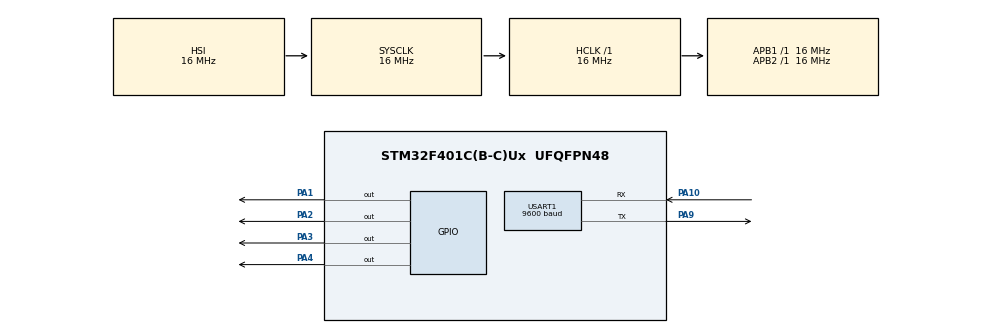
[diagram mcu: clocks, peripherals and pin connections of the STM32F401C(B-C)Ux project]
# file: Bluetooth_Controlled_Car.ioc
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Mcu.Family=STM32F4
Mcu.Name=STM32F401C(B-C)Ux
Mcu.Package=UFQFPN48
NVIC.PriorityGroup=NVIC_PRIORITYGROUP_4
NVIC.USART1_IRQn=true\:0\:0\:false\:false\:true\:true\:true
PA1.Signal=GPIO_Output
PA10.Mode=Asynchronous
PA10.Signal=USART1_RX
PA2.Signal=GPIO_Output
PA3.Signal=GPIO_Output
PA4.Signal=GPIO_Output
PA9.Mode=Asynchronous
PA9.Signal=USART1_TX
PH0\ -\ OSC_IN.Signal=RCC_OSC_IN
PH1\ -\ OSC_OUT.Signal=RCC_OSC_OUT
ProjectManager.HeapSize=0x200
ProjectManager.StackSize=0x400
ProjectManager.TargetToolchain=MDK-ARM V5.27
RCC.AHBFreq_Value=16000000
RCC.APB1Freq_Value=16000000
RCC.APB2Freq_Value=16000000
RCC.CortexFreq_Value=16000000
RCC.HSE_VALUE=25000000
RCC.HSI_VALUE=16000000
RCC.LSE_VALUE=32768
RCC.SYSCLKFreq_VALUE=16000000
RCC.VCOOutputFreq_Value=192000000
USART1.BaudRate=9600
USART1.Mode=MODE_RX
USART1.VirtualMode=VM_ASYNC
board=custom

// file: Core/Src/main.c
/* USER CODE BEGIN Header */
/**
  ******************************************************************************
  * @file           : main.c
  * @brief          : Main program body
  ******************************************************************************
  * @attention
  *
  * <h2><center>&copy; Copyright (c) 2021 STMicroelectronics.
  * All rights reserved.</center></h2>
  *
  * This software component is licensed by ST under BSD 3-Clause license,
  * the "License"; You may not use this file except in compliance with the
  * License. You may obtain a copy of the License at:
  *                        opensource.org/licenses/BSD-3-Clause
  *
  ******************************************************************************
  */
/* USER CODE END Header */
#include "main.h"

#define BUFFER_LEN  1

UART_HandleTypeDef huart1;

/* USER CODE BEGIN PV */

uint8_t RX_BUFFER[BUFFER_LEN] = {0};

/* USER CODE END PV */

void SystemClock_Config(void);
static void MX_GPIO_Init(void);
static void MX_USART1_UART_Init(void);

int main(void)
{

  /* MCU Configuration--------------------------------------------------------*/

  /* Reset of all peripherals, Initializes the Flash interface and the Systick. */
  HAL_Init();

  /* Configure the system clock */
  SystemClock_Config();

  /* Initialize all configured peripherals */
  MX_GPIO_Init();
  MX_USART1_UART_Init();
  /* USER CODE BEGIN 2 */
	HAL_UART_Receive_IT(&huart1, RX_BUFFER, BUFFER_LEN);
  /* USER CODE END 2 */

  /* Infinite loop */
  while (1)
  {
		if(RX_BUFFER[0] == 'F')			// Move Forward
    	{
    	    HAL_GPIO_WritePin(GPIOA, GPIO_PIN_1, 1);
					HAL_GPIO_WritePin(GPIOA, GPIO_PIN_2, 0);
					HAL_GPIO_WritePin(GPIOA, GPIO_PIN_3, 1);
					HAL_GPIO_WritePin(GPIOA, GPIO_PIN_4, 0);
    	}
    	else if(RX_BUFFER[0] == 'B')		// Move Backward
    	{
    	    HAL_GPIO_WritePin(GPIOA, GPIO_PIN_1, 0);
					HAL_GPIO_WritePin(GPIOA, GPIO_PIN_2, 1);
					HAL_GPIO_WritePin(GPIOA, GPIO_PIN_3, 0);
					HAL_GPIO_WritePin(GPIOA, GPIO_PIN_4, 1);
    	}
			else if(RX_BUFFER[0] == 'L')		// Turn Left
    	{
    	    HAL_GPIO_WritePin(GPIOA, GPIO_PIN_1, 1);
					HAL_GPIO_WritePin(GPIOA, GPIO_PIN_2, 0);
					HAL_GPIO_WritePin(GPIOA, GPIO_PIN_3, 0);
					HAL_GPIO_WritePin(GPIOA, GPIO_PIN_4, 1);
					HAL_Delay(1000);  // 1 sec delay
					RX_BUFFER[0] = 'S';
    	}
    	else if(RX_BUFFER[0] == 'R')		// Turn Right
    	{
    	    HAL_GPIO_WritePin(GPIOA, GPIO_PIN_1, 0);
					HAL_GPIO_WritePin(GPIOA, GPIO_PIN_2, 1);
					HAL_GPIO_WritePin(GPIOA, GPIO_PIN_3, 1);
					HAL_GPIO_WritePin(GPIOA, GPIO_PIN_4, 0);
					HAL_Delay(1000);  // 1 sec delay
					RX_BUFFER[0] = 'S';
    	}
			else if(RX_BUFFER[0] == 'S')		// Stop
    	{
    	    HAL_GPIO_WritePin(GPIOA, GPIO_PIN_1, 0);
					HAL_GPIO_WritePin(GPIOA, GPIO_PIN_2, 0);
					HAL_GPIO_WritePin(GPIOA, GPIO_PIN_3, 0);
					HAL_GPIO_WritePin(GPIOA, GPIO_PIN_4, 0);
    	}
  }
}

void HAL_UART_RxCpltCallback(UART_HandleTypeDef *huart)
{
    if(huart->Instance == huart1.Instance)
    {
	HAL_UART_Receive_IT(&huart1, RX_BUFFER, BUFFER_LEN);
    }
}
void SystemClock_Config(void)
{
  RCC_OscInitTypeDef RCC_OscInitStruct = {0};
  RCC_ClkInitTypeDef RCC_ClkInitStruct = {0};

  /** Configure the main internal regulator output voltage
  */
  __HAL_RCC_PWR_CLK_ENABLE();
  __HAL_PWR_VOLTAGESCALING_CONFIG(PWR_REGULATOR_VOLTAGE_SCALE2);
  /** Initializes the RCC Oscillators according to the specified parameters
  * in the RCC_OscInitTypeDef structure.
  */
  RCC_OscInitStruct.OscillatorType = RCC_OSCILLATORTYPE_HSI;
  RCC_OscInitStruct.HSIState = RCC_HSI_ON;
  RCC_OscInitStruct.HSICalibrationValue = RCC_HSICALIBRATION_DEFAULT;
  RCC_OscInitStruct.PLL.PLLState = RCC_PLL_NONE;
  if (HAL_RCC_OscConfig(&RCC_OscInitStruct) != HAL_OK)
  {
    Error_Handler();
  }
  /** Initializes the CPU, AHB and APB buses clocks
  */
  RCC_ClkInitStruct.ClockType = RCC_CLOCKTYPE_HCLK|RCC_CLOCKTYPE_SYSCLK
                              |RCC_CLOCKTYPE_PCLK1|RCC_CLOCKTYPE_PCLK2;
  RCC_ClkInitStruct.SYSCLKSource = RCC_SYSCLKSOURCE_HSI;
  RCC_ClkInitStruct.AHBCLKDivider = RCC_SYSCLK_DIV1;
  RCC_ClkInitStruct.APB1CLKDivider = RCC_HCLK_DIV1;
  RCC_ClkInitStruct.APB2CLKDivider = RCC_HCLK_DIV1;

  if (HAL_RCC_ClockConfig(&RCC_ClkInitStruct, FLASH_LATENCY_0) != HAL_OK)
  {
    Error_Handler();
  }
}

static void MX_USART1_UART_Init(void)
{

  huart1.Instance = USART1;
  huart1.Init.BaudRate = 9600;
  huart1.Init.WordLength = UART_WORDLENGTH_8B;
  huart1.Init.StopBits = UART_STOPBITS_1;
  huart1.Init.Parity = UART_PARITY_NONE;
  huart1.Init.Mode = UART_MODE_RX;
  huart1.Init.HwFlowCtl = UART_HWCONTROL_NONE;
  huart1.Init.OverSampling = UART_OVERSAMPLING_16;
  if (HAL_UART_Init(&huart1) != HAL_OK)
  {
    Error_Handler();
  }

}

static void MX_GPIO_Init(void)
{
  GPIO_InitTypeDef GPIO_InitStruct = {0};

  /* GPIO Ports Clock Enable */
  __HAL_RCC_GPIOH_CLK_ENABLE();
  __HAL_RCC_GPIOA_CLK_ENABLE();

  /*Configure GPIO pin Output Level */
  HAL_GPIO_WritePin(GPIOA, GPIO_PIN_1|GPIO_PIN_2|GPIO_PIN_3|GPIO_PIN_4, GPIO_PIN_RESET);

  /*Configure GPIO pins : PA1 PA2 PA3 PA4 */
  GPIO_InitStruct.Pin = GPIO_PIN_1|GPIO_PIN_2|GPIO_PIN_3|GPIO_PIN_4;
  GPIO_InitStruct.Mode = GPIO_MODE_OUTPUT_PP;
  GPIO_InitStruct.Pull = GPIO_NOPULL;
  GPIO_InitStruct.Speed = GPIO_SPEED_FREQ_LOW;
  HAL_GPIO_Init(GPIOA, &GPIO_InitStruct);

}

void Error_Handler(void)
{
  __disable_irq();
  while (1)
  {
  }
}

/*****END OF FILE****/
